# STM32U5A9 register map
File version: 1.7
CPU: CM33 r0p1, little endian, MPU, FPU, 4 interrupt priority bits
Registers are 32-bit, read-write, reset 0x0 unless marked. A register's access mark holds for its fields unless they carry their own. Offsets are from the block's base; [hi:lo] are bit positions; {n}, {i} and the like mark numbered series.

## FMAC — Filter Math Accelerator
Base 0x40021400
Same registers: SEC_FMAC 0x50021400
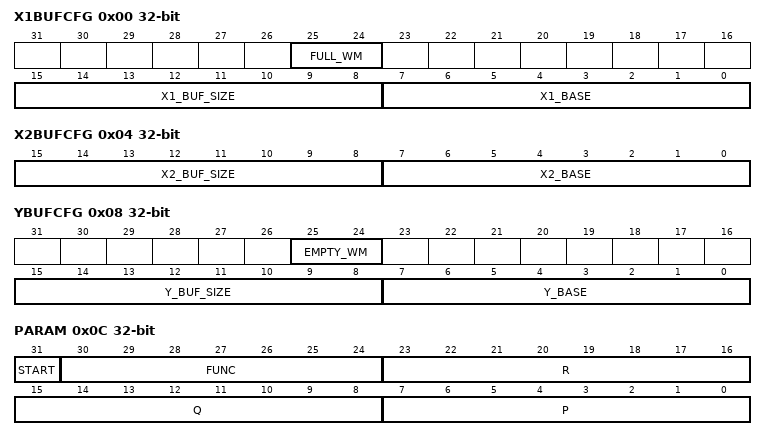
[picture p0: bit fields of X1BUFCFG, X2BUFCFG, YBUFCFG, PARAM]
0x00 X1BUFCFG — FMAC X1 Buffer Configuration register
  [25:24] FULL_WM — Watermark for buffer full flag
  [15:8] X1_BUF_SIZE — Allocated size of X1 buffer in 16-bit words
  [7:0] X1_BASE — Base address of X1 buffer
0x04 X2BUFCFG — FMAC X2 Buffer Configuration register
  [15:8] X2_BUF_SIZE — Size of X2 buffer in 16-bit words
  [7:0] X2_BASE — Base address of X2 buffer
0x08 YBUFCFG — FMAC Y Buffer Configuration register
  [25:24] EMPTY_WM — Watermark for buffer empty flag
  [15:8] Y_BUF_SIZE — Size of Y buffer in 16-bit words
  [7:0] Y_BASE — Base address of Y buffer
0x0C PARAM — FMAC Parameter register
  [31] START — Enable execution
  [30:24] FUNC — Function
  [23:16] R — Input parameter R
  [15:8] Q — Input parameter Q
  [7:0] P — Input parameter P
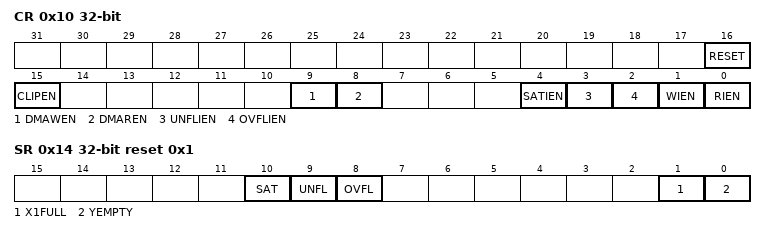
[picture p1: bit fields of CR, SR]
0x10 CR — FMAC Control register
  [16] RESET — Reset FMAC unit
  [15] CLIPEN — Enable clipping
  [9] DMAWEN — Enable DMA write channel requests
  [8] DMAREN — Enable DMA read channel requests
  [4] SATIEN — Enable saturation error interrupts
  [3] UNFLIEN — Enable underflow error interrupts
  [2] OVFLIEN — Enable overflow error interrupts
  [1] WIEN — Enable write interrupt
  [0] RIEN — Enable read interrupt
0x14 SR ro reset 0x1 — FMAC Status register
  [10] SAT — Saturation error flag
  [9] UNFL — Underflow error flag
  [8] OVFL — Overflow error flag
  [1] X1FULL — X1 buffer full flag
  [0] YEMPTY — Y buffer empty flag
0x18 WDATA wo — FMAC Write Data register
  [15:0] WDATA — Write data
0x1C RDATA ro — FMAC Read Data register
  [15:0] RDATA — Read data

## GFXMMU
Base 0x4002C000
Same registers: SEC_GFXMMU 0x5002C000
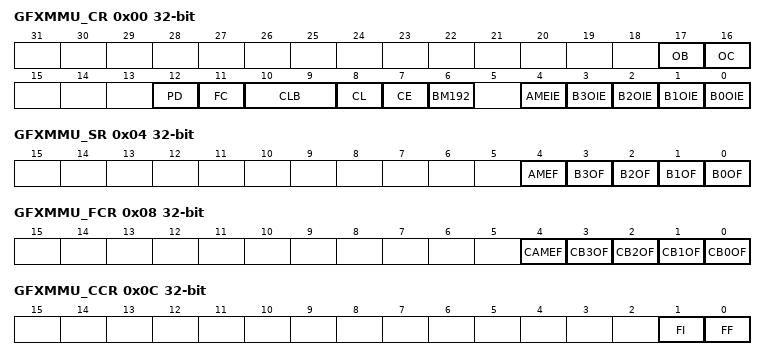
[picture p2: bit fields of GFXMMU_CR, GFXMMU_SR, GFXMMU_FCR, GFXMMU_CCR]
0x00 GFXMMU_CR — GFXMMU configuration register
  [17] OB — Outter bufferability
    0=No bufferable; 1=Bufferable
  [16] OC — Outter cachability
    0=No cachable; 1=Cachable
  [12] PD — Prefetch disable
    0=Prefetch enable; 1=Prefetch disable
  [11] FC — Force caching
    0=Caching not forced; 1=Caching forced
  [10:9] CLB — Cache lock buffer
    {v}=Cache locked on buffer {v} (v=0..3)
  [8] CL — Cache lock
    0=Cache not locked; 1=Cache locked to a buffer
  [7] CE — Cache enable
    0=Cache disable; 1=Cache enable
  [6] BM192 — 192 Block mode
    0=256 blocks per line; 1=192 blocks per line
  [4] AMEIE — AHB master error interrupt enable
    0=Interrupt disable; 1=Interrupt enabled
  [n] B{n}OIE (n=0..3) — Buffer {n} overflow interrupt enable
    0=Interrupt disable; 1=Interrupt enabled
0x04 GFXMMU_SR ro — GFXMMU status register
  [4] AMEF — AHB master error flag
  [n] B{n}OF (n=0..3) — Buffer {n} overflow flag
0x08 GFXMMU_FCR — GFXMMU flag clear register
  [4] CAMEF — Clear AHB master error flag
  [n] CB{n}OF (n=0..3) — Clear buffer {n} overflow flag
0x0C GFXMMU_CCR — GFXMMU cache control register
  [1] FI — Force invalidate
    0=Invalidation process complete; 1=Force invalidation/invalidation process on going
  [0] FF — Force flush
    0=Flushing process complete; 1=Force flush/flushing process on going
0x10 GFXMMU_DVR — GFXMMU default value register
  [31:0] DV — Default value
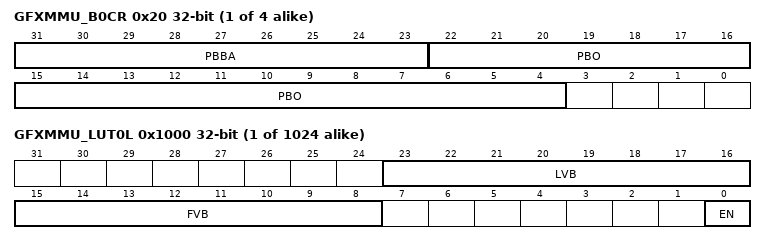
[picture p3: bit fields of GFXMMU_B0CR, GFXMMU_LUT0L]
{0x20+4i} GFXMMU_B{i}CR (i=0..3) — GFXMMU buffer {i} configuration register
  [31:23] PBBA — Physical buffer base address
  [22:4] PBO — Physical buffer offset
{0x1000+8i} GFXMMU_LUT{i}L (i=0..1023) — GFXMMU LUT entry {i} low
  [23:16] LVB — Last Valid Block
  [15:8] FVB — First Valid Block
  [0] EN — Enable
    0=Line is disabled (no MMU evaluation is performed); 1=Line is enabled (MMU evaluation is performed)
{0x1004+8i} GFXMMU_LUT{i}H (i=0..1023) — GFXMMU LUT entry {i} high
  [21:4] LO — Line offset

## GTZC1_MPCBB1
Base 0x40032C00
Same registers: SEC_GTZC1_MPCBB1 0x50032C00
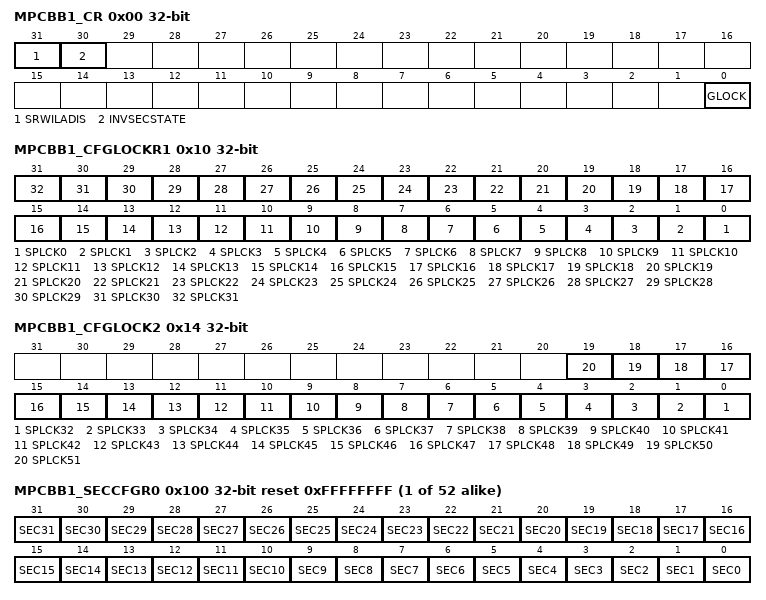
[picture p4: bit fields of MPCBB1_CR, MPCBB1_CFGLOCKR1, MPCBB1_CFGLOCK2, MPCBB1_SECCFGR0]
0x00 MPCBB1_CR — MPCBB control register
  [31] SRWILADIS — secure read/write illegal access disable
  [30] INVSECSTATE — SRAMx clocks security state
  [0] GLOCK — lock the control register of the MPCBB until next reset
0x10 MPCBB1_CFGLOCKR1 — GTZC1 SRAMz MPCBB configuration lock register 1
  [n] SPLCK{n} (n=0..31)
0x14 MPCBB1_CFGLOCK2 — GTZC1 SRAMz MPCBB configuration lock register 2
  [n-32] SPLCK{n} (n=32..51)
{0x100+4i} MPCBB1_SECCFGR{i} reset 0xFFFFFFFF (i=0..51) — MPCBBx security configuration for super-block x register
  [n] SEC{n} (n=0..31)
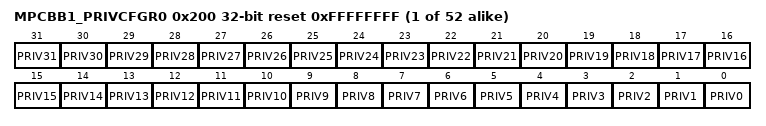
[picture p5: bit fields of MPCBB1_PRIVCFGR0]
{0x200+4i} MPCBB1_PRIVCFGR{i} reset 0xFFFFFFFF (i=0..51) — MPCBB privileged configuration for super-block x register
  [n] PRIV{n} (n=0..31)
